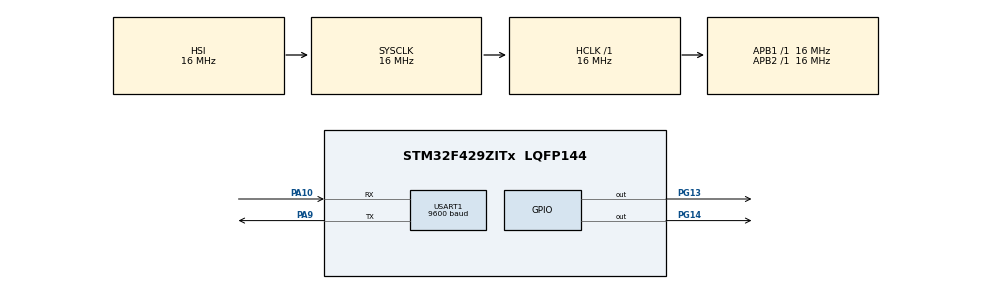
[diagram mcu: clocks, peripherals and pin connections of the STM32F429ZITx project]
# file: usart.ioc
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Mcu.Family=STM32F4
Mcu.Name=STM32F429ZITx
Mcu.Package=LQFP144
NVIC.PriorityGroup=NVIC_PRIORITYGROUP_4
PA10.Mode=Asynchronous
PA10.Signal=USART1_RX
PA9.Mode=Asynchronous
PA9.Signal=USART1_TX
PG13.Signal=GPIO_Output
PG14.Signal=GPIO_Output
ProjectManager.HeapSize=0x200
ProjectManager.StackSize=0x400
ProjectManager.TargetToolchain=STM32CubeIDE
RCC.AHBFreq_Value=16000000
RCC.APB1Freq_Value=16000000
RCC.APB2Freq_Value=16000000
RCC.CortexFreq_Value=16000000
RCC.HSE_VALUE=25000000
RCC.HSI_VALUE=16000000
RCC.LSE_VALUE=32768
RCC.SYSCLKFreq_VALUE=16000000
RCC.VCOOutputFreq_Value=192000000
USART1.BaudRate=9600
USART1.VirtualMode=VM_ASYNC
board=custom

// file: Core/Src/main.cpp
/* USER CODE BEGIN Header */
/**
  ******************************************************************************
  * @file           : main.c
  * @brief          : Main program body
  ******************************************************************************
  * @attention
  *
  * Copyright (c) 2025 STMicroelectronics.
  * All rights reserved.
  *
  * This software is licensed under terms that can be found in the LICENSE file
  * in the root directory of this software component.
  * If no LICENSE file comes with this software, it is provided AS-IS.
  *
  ******************************************************************************
  */
/* USER CODE END Header */
#include "main.hh"

UART_HandleTypeDef huart1;

/* USER CODE BEGIN PV */
uint8_t receivedData = 0;
/* USER CODE END PV */

void SystemClock_Config(void);
static void MX_GPIO_Init(void);
static void MX_USART1_UART_Init(void);

int main(void)
{

  /* MCU Configuration--------------------------------------------------------*/
  HAL_Init();  // Initialize HAL

  /* Configure the system clock */
  SystemClock_Config();

  /* Initialize all configured peripherals */
  MX_GPIO_Init();
  MX_USART1_UART_Init();

  /* Infinite loop */
  /* USER CODE BEGIN WHILE */
  while (1)
  {
    // Wait for data to be received on the RX pin
	  (HAL_UART_Transmit(&huart1, &transmitData,HAL_Delay; ) == HAL_OK)
    if (HAL_UART_Receive(&huart1, &receivedData,HAL_Delay; ) == HAL_OK)
    	// Timeout set to 1000ms
    {
      // Data received, toggle LED1 (PG13)
      HAL_GPIO_TogglePin(GPIOG, GPIO_PIN_13);  // Toggle LED1
      HAL_GPIO_TogglePin(GPIOG, GPIO_PIN_14);  // Toggle LED2
      HAL_Delay(500);  // LED blinking delay
    }
    else
    {
      // No data received, turn off LEDs
      HAL_GPIO_WritePin(GPIOG, GPIO_PIN_13, GPIO_PIN_RESET);
      HAL_GPIO_WritePin(GPIOG, GPIO_PIN_14, GPIO_PIN_RESET);
    }

  }
}

void SystemClock_Config(void)
{
  RCC_OscInitTypeDef RCC_OscInitStruct = {0};
  RCC_ClkInitTypeDef RCC_ClkInitStruct = {0};

  /** Configure the main internal regulator output voltage
  */
  __HAL_RCC_PWR_CLK_ENABLE();
  __HAL_PWR_VOLTAGESCALING_CONFIG(PWR_REGULATOR_VOLTAGE_SCALE3);

  /** Initializes the RCC Oscillators according to the specified parameters
  * in the RCC_OscInitTypeDef structure.
  */
  RCC_OscInitStruct.OscillatorType = RCC_OSCILLATORTYPE_HSI;
  RCC_OscInitStruct.HSIState = RCC_HSI_ON;
  RCC_OscInitStruct.HSICalibrationValue = RCC_HSICALIBRATION_DEFAULT;
  RCC_OscInitStruct.PLL.PLLState = RCC_PLL_NONE;
  if (HAL_RCC_OscConfig(&RCC_OscInitStruct) != HAL_OK)
  {
    Error_Handler();
  }

  /** Initializes the CPU, AHB and APB buses clocks
  */
  RCC_ClkInitStruct.ClockType = RCC_CLOCKTYPE_HCLK|RCC_CLOCKTYPE_SYSCLK
                              |RCC_CLOCKTYPE_PCLK1|RCC_CLOCKTYPE_PCLK2;
  RCC_ClkInitStruct.SYSCLKSource = RCC_SYSCLKSOURCE_HSI;
  RCC_ClkInitStruct.AHBCLKDivider = RCC_SYSCLK_DIV1;
  RCC_ClkInitStruct.APB1CLKDivider = RCC_HCLK_DIV1;
  RCC_ClkInitStruct.APB2CLKDivider = RCC_HCLK_DIV1;

  if (HAL_RCC_ClockConfig(&RCC_ClkInitStruct, FLASH_LATENCY_0) != HAL_OK)
  {
    Error_Handler();
  }
}

static void MX_USART1_UART_Init(void)
{
  huart1.Instance = USART1;
  huart1.Init.BaudRate = 9600;
  huart1.Init.WordLength = UART_WORDLENGTH_8B;
  huart1.Init.StopBits = UART_STOPBITS_1;
  huart1.Init.Parity = UART_PARITY_NONE;
  huart1.Init.Mode = UART_MODE_TX_RX;
  huart1.Init.HwFlowCtl = UART_HWCONTROL_NONE;
  huart1.Init.OverSampling = UART_OVERSAMPLING_16;
  if (HAL_UART_Init(&huart1) != HAL_OK)
  {
    Error_Handler();
  }
}

static void MX_GPIO_Init(void)
{
  GPIO_InitTypeDef GPIO_InitStruct = {0};

  /* GPIO Ports Clock Enable */
  __HAL_RCC_GPIOA_CLK_ENABLE();
  __HAL_RCC_GPIOG_CLK_ENABLE();

  /* Configure GPIO pin Output Level */
  HAL_GPIO_WritePin(GPIOG, GPIO_PIN_13|GPIO_PIN_14, GPIO_PIN_RESET);

  /* Configure GPIO pins : PG13 PG14 */
  GPIO_InitStruct.Pin = GPIO_PIN_13|GPIO_PIN_14;
  GPIO_InitStruct.Mode = GPIO_MODE_OUTPUT_PP;
  GPIO_InitStruct.Pull = GPIO_NOPULL;
  GPIO_InitStruct.Speed = GPIO_SPEED_FREQ_LOW;
  HAL_GPIO_Init(GPIOG, &GPIO_InitStruct);

  /* Configure TX pin (PA9) for output */
  GPIO_InitStruct.Pin = GPIO_PIN_9;
  GPIO_InitStruct.Mode = GPIO_MODE_OUTPUT_PP;
  GPIO_InitStruct.Pull = GPIO_NOPULL;
  GPIO_InitStruct.Speed = GPIO_SPEED_FREQ_LOW;
  HAL_GPIO_Init(GPIOA, &GPIO_InitStruct);

  /* Configure RX pin (PA10) for input with pull-up resistor */
  GPIO_InitStruct.Pin = GPIO_PIN_10;
  GPIO_InitStruct.Mode = GPIO_MODE_INPUT;
  GPIO_InitStruct.Pull = GPIO_PULLUP;  // Enable pull-up resistor for the RX pin
  HAL_GPIO_Init(GPIOA, &GPIO_InitStruct);
}

void Error_Handler(void)
{
  __disable_irq();
  while (1)
  {
  }
}
